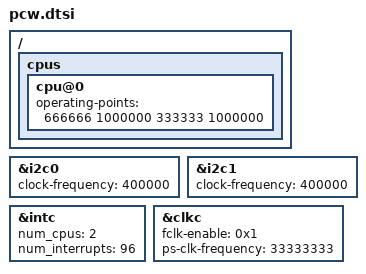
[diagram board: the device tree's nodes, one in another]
/*
 * CAUTION: This file is automatically generated by Xilinx.
 * Version:  
 * Today is: Tue Jul 17 11:26:20 2018
 */


/ {
	cpus {
		cpu@0 {
			operating-points = <666666 1000000 333333 1000000>;
		};
	};
};
&i2c0 {
	clock-frequency = <400000>;
	status = "okay";
};
&i2c1 {
	clock-frequency = <400000>;
	status = "okay";
};
&intc {
	num_cpus = <2>;
	num_interrupts = <96>;
};
&clkc {
	fclk-enable = <0x1>;
	ps-clk-frequency = <33333333>;
};
